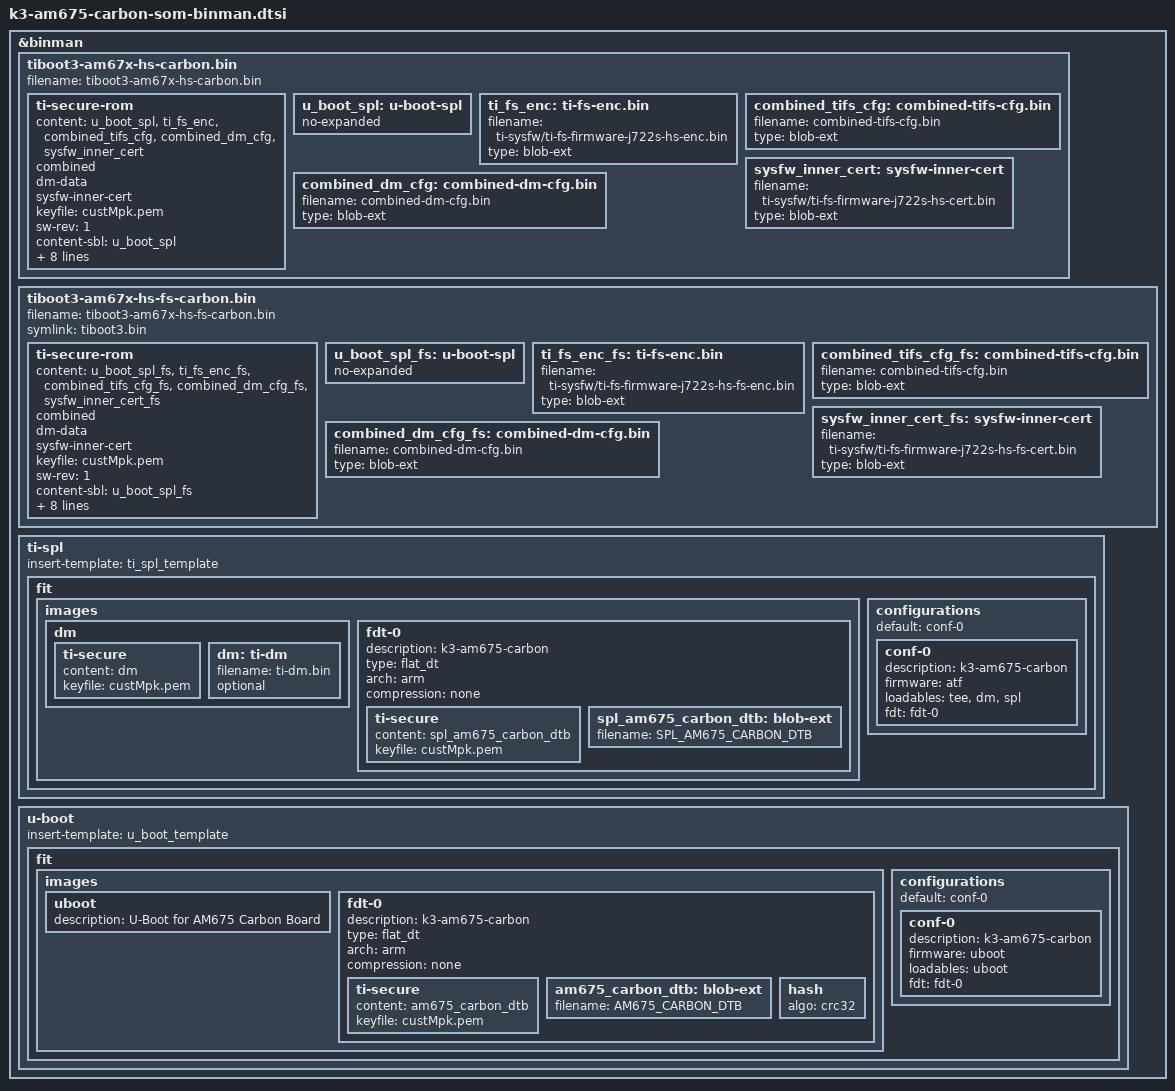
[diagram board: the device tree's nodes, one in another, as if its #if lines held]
// SPDX-License-Identifier: GPL-2.0
/*
 * Copyright (C) 2025 Ezurio
 */

#include "k3-binman.dtsi"

#if IS_ENABLED(CONFIG_TARGET_CARBON_AM67_R5)

&binman {
	tiboot3-am67x-hs-carbon.bin {
		filename = "tiboot3-am67x-hs-carbon.bin";
		ti-secure-rom {
			content = <&u_boot_spl>, <&ti_fs_enc>, <&combined_tifs_cfg>,
				  <&combined_dm_cfg>, <&sysfw_inner_cert>;
			combined;
			dm-data;
			sysfw-inner-cert;
			keyfile = "custMpk.pem";
			sw-rev = <1>;
			content-sbl = <&u_boot_spl>;
			content-sysfw = <&ti_fs_enc>;
			content-sysfw-data = <&combined_tifs_cfg>;
			content-sysfw-inner-cert = <&sysfw_inner_cert>;
			content-dm-data = <&combined_dm_cfg>;
			load = <CONFIG_SPL_TEXT_BASE>;
			load-sysfw = <0x40000>;
			load-sysfw-data = <0x67000>;
			load-dm-data = <0x43c7a800>;
		};

		u_boot_spl: u-boot-spl {
			no-expanded;
		};

		ti_fs_enc: ti-fs-enc.bin {
			filename = "ti-sysfw/ti-fs-firmware-j722s-hs-enc.bin";
			type = "blob-ext";
		};

		combined_tifs_cfg: combined-tifs-cfg.bin {
			filename = "combined-tifs-cfg.bin";
			type = "blob-ext";
		};

		sysfw_inner_cert: sysfw-inner-cert {
			filename = "ti-sysfw/ti-fs-firmware-j722s-hs-cert.bin";
			type = "blob-ext";
		};

		combined_dm_cfg: combined-dm-cfg.bin {
			filename = "combined-dm-cfg.bin";
			type = "blob-ext";
		};
	};
};

&binman {
	tiboot3-am67x-hs-fs-carbon.bin {
		filename = "tiboot3-am67x-hs-fs-carbon.bin";
		symlink = "tiboot3.bin";

		ti-secure-rom {
			content = <&u_boot_spl_fs>, <&ti_fs_enc_fs>, <&combined_tifs_cfg_fs>,
				  <&combined_dm_cfg_fs>, <&sysfw_inner_cert_fs>;
			combined;
			dm-data;
			sysfw-inner-cert;
			keyfile = "custMpk.pem";
			sw-rev = <1>;
			content-sbl = <&u_boot_spl_fs>;
			content-sysfw = <&ti_fs_enc_fs>;
			content-sysfw-data = <&combined_tifs_cfg_fs>;
			content-sysfw-inner-cert = <&sysfw_inner_cert_fs>;
			content-dm-data = <&combined_dm_cfg_fs>;
			load = <CONFIG_SPL_TEXT_BASE>;
			load-sysfw = <0x40000>;
			load-sysfw-data = <0x67000>;
			load-dm-data = <0x43c7a800>;
		};

		u_boot_spl_fs: u-boot-spl {
			no-expanded;
		};

		ti_fs_enc_fs: ti-fs-enc.bin {
			filename = "ti-sysfw/ti-fs-firmware-j722s-hs-fs-enc.bin";
			type = "blob-ext";
		};

		combined_tifs_cfg_fs: combined-tifs-cfg.bin {
			filename = "combined-tifs-cfg.bin";
			type = "blob-ext";
		};

		sysfw_inner_cert_fs: sysfw-inner-cert {
			filename = "ti-sysfw/ti-fs-firmware-j722s-hs-fs-cert.bin";
			type = "blob-ext";
		};

		combined_dm_cfg_fs: combined-dm-cfg.bin {
			filename = "combined-dm-cfg.bin";
			type = "blob-ext";
		};
	};
};

#endif /* CONFIG_TARGET_CARBON_AM67_R5 */

#if IS_ENABLED(CONFIG_TARGET_CARBON_AM67_A53)

#if !defined(CONFIG_SPL_MULTI_DTB_FIT)
#undef SPL_AM675_CARBON_DTB
#define SPL_AM675_CARBON_DTB "spl/dts/dt-spl.dtb"
#endif
#define AM675_CARBON_DTB "u-boot.dtb"

&binman {
	ti-spl {
		insert-template = <&ti_spl_template>;

		fit {
			images {
				dm {
					ti-secure {
						content = <&dm>;
						keyfile = "custMpk.pem";
					};

					dm: ti-dm {
						filename = "ti-dm.bin";
						optional;
					};
				};

				fdt-0 {
					description = "k3-am675-carbon";
					type = "flat_dt";
					arch = "arm";
					compression = "none";

					ti-secure {
						content = <&spl_am675_carbon_dtb>;
						keyfile = "custMpk.pem";
					};

					spl_am675_carbon_dtb: blob-ext {
						filename = SPL_AM675_CARBON_DTB;
					};

				};

			};

			configurations {
				default = "conf-0";

				conf-0 {
					description = "k3-am675-carbon";
					firmware = "atf";
					loadables = "tee", "dm", "spl";
					fdt = "fdt-0";
				};
			};
		};
	};
};

&binman {
	u-boot {
		insert-template = <&u_boot_template>;

		fit {
			images {
				uboot {
					description = "U-Boot for AM675 Carbon Board";
				};

				fdt-0 {
					description = "k3-am675-carbon";
					type = "flat_dt";
					arch = "arm";
					compression = "none";

					ti-secure {
						content = <&am675_carbon_dtb>;
						keyfile = "custMpk.pem";
					};

					am675_carbon_dtb: blob-ext {
						filename = AM675_CARBON_DTB;
					};

					hash {
						algo = "crc32";
					};
				};
			};

			configurations {
				default = "conf-0";

				conf-0 {
					description = "k3-am675-carbon";
					firmware = "uboot";
					loadables = "uboot";
					fdt = "fdt-0";
				};

			};
		};
	};
};
#endif /* CONFIG_TARGET_CARBON_AM67_A53 */
